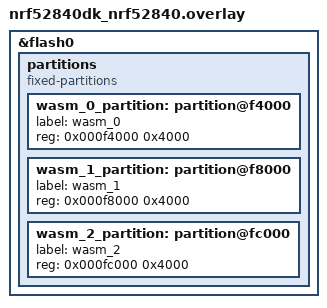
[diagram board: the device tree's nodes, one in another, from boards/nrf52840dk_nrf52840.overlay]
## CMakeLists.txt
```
cmake_minimum_required(VERSION 3.14)

find_package(Zephyr REQUIRED HINTS $ENV{ZEPHYR_BASE})
project(wamr_ota)

enable_language(ASM)

set(WAMR_BUILD_PLATFORM "zephyr")

if(NOT DEFINED WAMR_BUILD_TARGET)
  set(WAMR_BUILD_TARGET "THUMBV7")
endif()

set(WAMR_BUILD_INTERP 1)
set(WAMR_BUILD_FAST_INTERP 1)
set(WAMR_BUILD_AOT 0)
set(WAMR_BUILD_JIT 0)
set(WAMR_BUILD_LIBC_BUILTIN 1)
set(WAMR_BUILD_LIBC_WASI 0)
set(WAMR_BUILD_MINI_LOADER 0)
set(WAMR_BUILD_MULTI_MODULE 0)
set(WAMR_BUILD_REF_TYPES 0)
set(WAMR_BUILD_SIMD 0)

set(WAMR_BUILD_GLOBAL_HEAP_POOL 1)

if(BOARD STREQUAL "nucleo_l476rg")
  set(WAMR_BUILD_GLOBAL_HEAP_SIZE 73728)
  set(WASM_OTA_BUF_SIZE 2048)
  set(WASM_STACK_SIZE 2048)
  set(WASM_HEAP_SIZE 2048)
else()
  set(WAMR_BUILD_GLOBAL_HEAP_SIZE 225280)
  set(WASM_OTA_BUF_SIZE 8192)
  set(WASM_STACK_SIZE 2048)
  set(WASM_HEAP_SIZE 0)
endif()

if(EXISTS ${CMAKE_CURRENT_SOURCE_DIR}/../wasm-micro-runtime)
  set(WAMR_ROOT_DIR ${CMAKE_CURRENT_SOURCE_DIR}/../wasm-micro-runtime)
else()
  set(WAMR_ROOT_DIR ${CMAKE_CURRENT_SOURCE_DIR}/../modules/wasm-micro-runtime)
endif()

include(${WAMR_ROOT_DIR}/build-scripts/runtime_lib.cmake)

target_sources(app PRIVATE
    ${WAMR_RUNTIME_LIB_SOURCE}
    src/main.c
    src/supervisor.c
    src/wasm_runner.c
    src/uart_loader.c
    src/wasm_flash.c
    src/native_api.c
)

target_compile_definitions(app PRIVATE
    WASM_OTA_BUF_SIZE=${WASM_OTA_BUF_SIZE}
    WASM_STACK_SIZE=${WASM_STACK_SIZE}
    WASM_HEAP_SIZE=${WASM_HEAP_SIZE}
)
target_compile_options(app PRIVATE -Wno-type-limits)
```

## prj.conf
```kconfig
CONFIG_STACK_SENTINEL=y
CONFIG_PRINTK=y
CONFIG_LOG=y
CONFIG_LOG_BUFFER_SIZE=4096

# Keep stacks small to leave RAM for WAMR heap
CONFIG_MAIN_STACK_SIZE=2048

# UART for OTA wasm upload (shared with console)
CONFIG_SERIAL=y
CONFIG_UART_INTERRUPT_DRIVEN=y
CONFIG_RING_BUFFER=y

# CRC-32 for upload validation
CONFIG_CRC=y
```

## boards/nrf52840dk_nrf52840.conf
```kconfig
CONFIG_ARM_MPU=y
CONFIG_GPIO=y
CONFIG_LOG_BUFFER_SIZE=4096

# Flash persistence for OTA wasm
CONFIG_FLASH=y
CONFIG_FLASH_MAP=y
```

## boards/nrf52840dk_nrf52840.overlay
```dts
&flash0 {
	partitions {
		compatible = "fixed-partitions";
		#address-cells = <1>;
		#size-cells = <1>;

		wasm_0_partition: partition@f4000 {
			label = "wasm_0";
			reg = <0x000f4000 0x4000>;
		};

		wasm_1_partition: partition@f8000 {
			label = "wasm_1";
			reg = <0x000f8000 0x4000>;
		};

		wasm_2_partition: partition@fc000 {
			label = "wasm_2";
			reg = <0x000fc000 0x4000>;
		};
	};
};
```

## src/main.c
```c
#include <stdlib.h>
#include <string.h>
#include <zephyr/kernel.h>
#include "wasm_export.h"
#include "supervisor.h"
#include "native_api.h"

static char global_heap_buf[WASM_GLOBAL_HEAP_SIZE];

int main(void)
{
    printk("--- WAMR Multi-Module Runtime ---\n");

    if (native_api_init() != 0) {
        printk("GPIO init failed\n");
        return 1;
    }

    RuntimeInitArgs init_args;
    memset(&init_args, 0, sizeof(init_args));
    init_args.mem_alloc_type = Alloc_With_Pool;
    init_args.mem_alloc_option.pool.heap_buf = global_heap_buf;
    init_args.mem_alloc_option.pool.heap_size = sizeof(global_heap_buf);

    if (!wasm_runtime_full_init(&init_args)) {
        printk("WAMR init failed\n");
        return 1;
    }

    native_api_register();

    supervisor_start();
    return 0;
}
```

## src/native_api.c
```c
#include <zephyr/kernel.h>
#include <zephyr/drivers/gpio.h>
#include "wasm_export.h"
#include "native_api.h"

#define NUM_BUTTONS 4
#define NUM_LEDS    4
#define NUM_DATA    16

static const struct gpio_dt_spec buttons[NUM_BUTTONS] = {
    GPIO_DT_SPEC_GET(DT_ALIAS(sw0), gpios),
    GPIO_DT_SPEC_GET(DT_ALIAS(sw1), gpios),
    GPIO_DT_SPEC_GET(DT_ALIAS(sw2), gpios),
    GPIO_DT_SPEC_GET(DT_ALIAS(sw3), gpios),
};

static const struct gpio_dt_spec leds[NUM_LEDS] = {
    GPIO_DT_SPEC_GET(DT_ALIAS(led0), gpios),
    GPIO_DT_SPEC_GET(DT_ALIAS(led1), gpios),
    GPIO_DT_SPEC_GET(DT_ALIAS(led2), gpios),
    GPIO_DT_SPEC_GET(DT_ALIAS(led3), gpios),
};

static int32_t shared_data[NUM_DATA];

static int32_t
native_read_button(wasm_exec_env_t exec_env, int32_t n)
{
    (void)exec_env;
    if (n < 0 || n >= NUM_BUTTONS)
        return -1;
    return gpio_pin_get_dt(&buttons[n]);
}

static void
native_set_led(wasm_exec_env_t exec_env, int32_t n, int32_t on)
{
    (void)exec_env;
    if (n >= 0 && n < NUM_LEDS)
        gpio_pin_set_dt(&leds[n], on ? 1 : 0);
}

static void
native_set_data(wasm_exec_env_t exec_env, int32_t key, int32_t value)
{
    (void)exec_env;
    if (key >= 0 && key < NUM_DATA)
        shared_data[key] = value;
}

static int32_t
native_get_data(wasm_exec_env_t exec_env, int32_t key)
{
    (void)exec_env;
    if (key < 0 || key >= NUM_DATA)
        return 0;
    return shared_data[key];
}

static NativeSymbol native_symbols[] = {
    { "read_button", native_read_button, "(i)i", NULL },
    { "set_led",     native_set_led,     "(ii)", NULL },
    { "set_data",    native_set_data,    "(ii)", NULL },
    { "get_data",    native_get_data,    "(i)i", NULL },
};

int
native_api_init(void)
{
    for (int i = 0; i < NUM_BUTTONS; i++) {
        if (!gpio_is_ready_dt(&buttons[i])) {
            printk("[native] button %d not ready\n", i);
            return -1;
        }
        gpio_pin_configure_dt(&buttons[i], GPIO_INPUT);
    }

    for (int i = 0; i < NUM_LEDS; i++) {
        if (!gpio_is_ready_dt(&leds[i])) {
            printk("[native] LED %d not ready\n", i);
            return -1;
        }
        gpio_pin_configure_dt(&leds[i], GPIO_OUTPUT_INACTIVE);
    }

    memset(shared_data, 0, sizeof(shared_data));
    printk("[native] GPIO ready: %d buttons, %d LEDs\n", NUM_BUTTONS, NUM_LEDS);
    return 0;
}

void
native_api_register(void)
{
    wasm_runtime_register_natives("env", native_symbols,
                                 sizeof(native_symbols) / sizeof(NativeSymbol));
}
```

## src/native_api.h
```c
#ifndef NATIVE_API_H
#define NATIVE_API_H

int native_api_init(void);

void native_api_register(void);

#endif
```

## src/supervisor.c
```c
#include <zephyr/kernel.h>
#include "supervisor.h"
#include "wasm_runner.h"
#include "wasm_flash.h"
#include "uart_loader.h"

#define SUPERVISOR_STACK_SIZE 2048
#define WASM_BUF_SIZE 8192

static uint8_t wasm_buf[WASM_BUF_SIZE];

static K_THREAD_STACK_DEFINE(supervisor_stack, SUPERVISOR_STACK_SIZE);
static struct k_thread supervisor_thread;

/* Embedded defaults for first boot (generated by build.sh) */
#include "wasm_sensor.h"
#include "wasm_actuator.h"
#include "wasm_alert.h"

static const char *slot_names[] = { "sensor", "actuator", "alert" };

struct embedded_default {
    unsigned char *data;
    unsigned int *len;
};

static struct embedded_default defaults[WASM_NUM_SLOTS];

static bool
load_slot(int slot)
{
    uint32_t size = wasm_flash_read(slot, wasm_buf, sizeof(wasm_buf));
    if (size == 0)
        return false;
    return wasm_runner_load(slot, slot_names[slot], wasm_buf, size);
}

static void
supervisor_entry(void *p1, void *p2, void *p3)
{
    (void)p1; (void)p2; (void)p3;

    defaults[0] = (struct embedded_default){ wasm_sensor, &wasm_sensor_len };
    defaults[1] = (struct embedded_default){ wasm_actuator, &wasm_actuator_len };
    defaults[2] = (struct embedded_default){ wasm_alert, &wasm_alert_len };

    wasm_runner_init();

    if (wasm_flash_init() != 0) {
        printk("[supervisor] flash init failed\n");
        return;
    }

    if (uart_loader_init() != 0) {
        printk("[supervisor] UART init failed\n");
        return;
    }

    /* Load all modules from flash (write defaults on first boot) */
    for (int i = 0; i < WASM_NUM_SLOTS; i++) {
        if (!wasm_flash_valid(i)) {
            printk("[supervisor] writing default %s to slot %d\n",
                   slot_names[i], i);
            wasm_flash_write(i, defaults[i].data, *defaults[i].len);
        }
        if (!load_slot(i)) {
            printk("[supervisor] slot %d (%s) failed to load!\n",
                   i, slot_names[i]);
        }
    }

    printk("[supervisor] all modules loaded, running...\n");

    while (1) {
        /* Run all loaded modules (no load/unload per cycle) */
        wasm_runner_run_all();

        /* Check for OTA upload */
        uint32_t wasm_size = 0;
        int target_slot = -1;
        int result = uart_loader_poll(wasm_buf, sizeof(wasm_buf),
                                      &wasm_size, &target_slot, 50);

        switch (result) {
        case LOADER_COMPLETE:
            if (target_slot < 0 || target_slot >= WASM_NUM_SLOTS) {
                uart_loader_respond("ERR:SLOT\n");
                break;
            }

            printk("[supervisor] OTA slot %d (%s): %u bytes\n",
                   target_slot, slot_names[target_slot], wasm_size);

            if (wasm_flash_write(target_slot, wasm_buf, wasm_size) != 0) {
                uart_loader_respond("ERR:FLASH\n");
                break;
            }

            /* Unload old, reload from flash */
            wasm_runner_unload(target_slot);
            if (load_slot(target_slot)) {
                uart_loader_respond("OK\n");
                printk("[supervisor] %s updated\n", slot_names[target_slot]);
            } else {
                uart_loader_respond("ERR:LOAD\n");
                printk("[supervisor] reload failed, restoring default\n");
                wasm_flash_write(target_slot, defaults[target_slot].data,
                                 *defaults[target_slot].len);
                load_slot(target_slot);
            }
            break;

        case LOADER_ERR_CRC:
            uart_loader_respond("ERR:CRC\n");
            break;

        case LOADER_ERR_SIZE:
            uart_loader_respond("ERR:SIZE\n");
            break;

        case LOADER_STATUS:
            uart_loader_respond("RUNNING\n");
            break;

        default:
            break;
        }

        k_sleep(K_MSEC(50));
    }
}

void
supervisor_start(void)
{
    k_thread_create(&supervisor_thread, supervisor_stack,
                    SUPERVISOR_STACK_SIZE, supervisor_entry,
                    NULL, NULL, NULL, 3, 0, K_NO_WAIT);
    k_thread_name_set(&supervisor_thread, "supervisor");
}
```

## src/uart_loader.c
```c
#include <string.h>
#include <zephyr/kernel.h>
#include <zephyr/device.h>
#include <zephyr/drivers/uart.h>
#include <zephyr/sys/ring_buffer.h>
#include <zephyr/sys/crc.h>
#include "uart_loader.h"

#define UART_RING_BUF_SIZE 1024

static const uint8_t MAGIC[4] = { 'W', 'A', 'S', 'M' };

typedef enum {
    RX_IDLE,
    RX_HEADER,
    RX_PAYLOAD,
    RX_CRC,
} rx_state_t;

static const struct device *uart_dev;
static uint8_t ring_buf_data[UART_RING_BUF_SIZE];
static struct ring_buf rx_ring;

static rx_state_t rx_state;
static uint8_t magic_window[4];
static uint8_t header_buf[7];
static uint32_t header_pos;
static uint32_t payload_pos;
static uint32_t expected_size;
static uint8_t expected_cmd;
static uint8_t expected_slot;
static uint8_t crc_buf[4];
static uint32_t crc_pos;

static int *slot_out_ptr;

static void
uart_isr_callback(const struct device *dev, void *user_data)
{
    (void)user_data;

    while (uart_irq_update(dev) && uart_irq_is_pending(dev)) {
        if (uart_irq_rx_ready(dev)) {
            uint8_t buf[64];
            int len = uart_fifo_read(dev, buf, sizeof(buf));
            if (len > 0)
                ring_buf_put(&rx_ring, buf, len);
        }
    }
}

int
uart_loader_init(void)
{
    uart_dev = DEVICE_DT_GET(DT_CHOSEN(zephyr_console));
    if (!device_is_ready(uart_dev)) {
        printk("[loader] UART device not ready\n");
        return -1;
    }

    ring_buf_init(&rx_ring, sizeof(ring_buf_data), ring_buf_data);

    uart_irq_callback_set(uart_dev, uart_isr_callback);
    uart_irq_rx_enable(uart_dev);

    rx_state = RX_IDLE;
    memset(magic_window, 0, sizeof(magic_window));

    printk("[loader] UART RX ready\n");
    return 0;
}

void
uart_loader_respond(const char *msg)
{
    while (*msg) {
        uart_poll_out(uart_dev, *msg++);
    }
}

static int
process_byte(uint8_t b, uint8_t *buf, uint32_t buf_size, uint32_t *out_size)
{
    switch (rx_state) {
    case RX_IDLE:
        memmove(magic_window, magic_window + 1, 3);
        magic_window[3] = b;
        if (memcmp(magic_window, MAGIC, 4) == 0) {
            rx_state = RX_HEADER;
            header_pos = 0;
            memset(magic_window, 0, sizeof(magic_window));
        }
        break;

    case RX_HEADER:
        header_buf[header_pos++] = b;
        /* Header: CMD(1) + SLOT(1) + SIZE(4) + '\n'(1) = 7 bytes */
        if (header_pos == 7) {
            expected_cmd = header_buf[0];
            expected_slot = header_buf[1];
            expected_size = header_buf[2]
                          | (header_buf[3] << 8)
                          | (header_buf[4] << 16)
                          | (header_buf[5] << 24);

            if (slot_out_ptr)
                *slot_out_ptr = expected_slot;

            if (expected_cmd == CMD_STATUS) {
                rx_state = RX_IDLE;
                *out_size = 0;
                return LOADER_STATUS;
            }

            if (expected_size == 0 || expected_size > buf_size) {
                printk("[loader] size %u exceeds buffer %u\n",
                       expected_size, buf_size);
                rx_state = RX_IDLE;
                return LOADER_ERR_SIZE;
            }

            payload_pos = 0;
            rx_state = RX_PAYLOAD;
        }
        break;

    case RX_PAYLOAD:
        buf[payload_pos++] = b;
        if (payload_pos == expected_size) {
            crc_pos = 0;
            rx_state = RX_CRC;
        }
        break;

    case RX_CRC:
        crc_buf[crc_pos++] = b;
        if (crc_pos == 4) {
            uint32_t received_crc = crc_buf[0]
                                  | (crc_buf[1] << 8)
                                  | (crc_buf[2] << 16)
                                  | (crc_buf[3] << 24);
            uint32_t computed_crc = crc32_ieee(buf, expected_size);

            rx_state = RX_IDLE;

            if (received_crc != computed_crc) {
                printk("[loader] CRC mismatch: got 0x%08x, expected 0x%08x\n",
                       received_crc, computed_crc);
                return LOADER_ERR_CRC;
            }

            *out_size = expected_size;
            return LOADER_COMPLETE;
        }
        break;
    }

    return (rx_state == RX_IDLE) ? LOADER_IDLE : LOADER_RECEIVING;
}

int
uart_loader_poll(uint8_t *buf, uint32_t buf_size,
                 uint32_t *out_size, int *out_slot,
                 int32_t timeout_ms)
{
    int64_t deadline = k_uptime_get() + timeout_ms;
    int result = LOADER_IDLE;

    slot_out_ptr = out_slot;

    while (k_uptime_get() < deadline) {
        uint8_t b;
        if (ring_buf_get(&rx_ring, &b, 1) == 1) {
            result = process_byte(b, buf, buf_size, out_size);
            if (result != LOADER_IDLE && result != LOADER_RECEIVING)
                return result;
        } else {
            k_sleep(K_MSEC(1));
        }
    }

    return result;
}
```

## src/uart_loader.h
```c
#ifndef UART_LOADER_H
#define UART_LOADER_H

#include <stdint.h>

#define LOADER_IDLE       0
#define LOADER_RECEIVING  1
#define LOADER_COMPLETE   2
#define LOADER_STATUS     3
#define LOADER_ERR_CRC   -1
#define LOADER_ERR_SIZE  -2

#define CMD_UPLOAD  0x01
#define CMD_STATUS  0x02

int uart_loader_init(void);

int uart_loader_poll(uint8_t *buf, uint32_t buf_size,
                     uint32_t *out_size, int *out_slot,
                     int32_t timeout_ms);

void uart_loader_respond(const char *msg);

#endif
```

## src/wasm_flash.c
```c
#include <string.h>
#include <zephyr/kernel.h>
#include <zephyr/storage/flash_map.h>
#include <zephyr/sys/crc.h>
#include "wasm_flash.h"

#define WASM_SLOT_MAGIC  0x4D534157
#define HEADER_SIZE      32
#define DATA_OFFSET      HEADER_SIZE
#define ALIGN4(x)        (((x) + 3) & ~3)

struct wasm_slot_header {
    uint32_t magic;
    uint32_t size;
    uint32_t crc32;
    uint32_t version;
    uint8_t  reserved[16];
};

static const struct flash_area *slot_fa[WASM_NUM_SLOTS];
static bool initialized;

static const int slot_partition_ids[WASM_NUM_SLOTS] = {
    FIXED_PARTITION_ID(wasm_0_partition),
    FIXED_PARTITION_ID(wasm_1_partition),
    FIXED_PARTITION_ID(wasm_2_partition),
};

int
wasm_flash_init(void)
{
    for (int i = 0; i < WASM_NUM_SLOTS; i++) {
        int rc = flash_area_open(slot_partition_ids[i], &slot_fa[i]);
        if (rc) {
            printk("[flash] failed to open slot %d: %d\n", i, rc);
            return rc;
        }
    }

    printk("[flash] %d slots ready (%u bytes each)\n",
           WASM_NUM_SLOTS, (unsigned)slot_fa[0]->fa_size);

    initialized = true;
    return 0;
}

static bool
read_header(int slot, struct wasm_slot_header *hdr)
{
    if (!initialized || slot < 0 || slot >= WASM_NUM_SLOTS)
        return false;
    return flash_area_read(slot_fa[slot], 0, hdr, sizeof(*hdr)) == 0;
}

bool
wasm_flash_valid(int slot)
{
    struct wasm_slot_header hdr;

    if (!read_header(slot, &hdr))
        return false;

    if (hdr.magic != WASM_SLOT_MAGIC)
        return false;

    if (hdr.size == 0 || hdr.size > slot_fa[slot]->fa_size - DATA_OFFSET)
        return false;

    uint8_t buf[256];
    uint32_t crc = 0;
    uint32_t remaining = hdr.size;
    uint32_t offset = DATA_OFFSET;

    while (remaining > 0) {
        uint32_t chunk = remaining < sizeof(buf) ? remaining : sizeof(buf);
        if (flash_area_read(slot_fa[slot], offset, buf, chunk) != 0)
            return false;
        crc = crc32_ieee_update(crc, buf, chunk);
        offset += chunk;
        remaining -= chunk;
    }

    return crc == hdr.crc32;
}

uint32_t
wasm_flash_version(int slot)
{
    struct wasm_slot_header hdr;
    if (!read_header(slot, &hdr) || hdr.magic != WASM_SLOT_MAGIC)
        return 0;
    return hdr.version;
}

uint32_t
wasm_flash_read(int slot, uint8_t *buf, uint32_t buf_size)
{
    struct wasm_slot_header hdr;
    if (!read_header(slot, &hdr))
        return 0;
    if (hdr.magic != WASM_SLOT_MAGIC || hdr.size == 0)
        return 0;
    if (hdr.size > buf_size)
        return 0;
    if (flash_area_read(slot_fa[slot], DATA_OFFSET, buf, hdr.size) != 0)
        return 0;

    uint32_t crc = crc32_ieee(buf, hdr.size);
    if (crc != hdr.crc32) {
        printk("[flash] slot %d CRC mismatch\n", slot);
        return 0;
    }

    return hdr.size;
}

int
wasm_flash_write(int slot, const uint8_t *data, uint32_t size)
{
    if (!initialized || slot < 0 || slot >= WASM_NUM_SLOTS)
        return -1;

    if (size + DATA_OFFSET > slot_fa[slot]->fa_size)
        return -1;

    struct wasm_slot_header hdr;
    memset(&hdr, 0, sizeof(hdr));
    hdr.magic = WASM_SLOT_MAGIC;
    hdr.size = size;
    hdr.crc32 = crc32_ieee(data, size);
    hdr.version = wasm_flash_version(slot) + 1;

    int rc = flash_area_erase(slot_fa[slot], 0, slot_fa[slot]->fa_size);
    if (rc) return rc;

    rc = flash_area_write(slot_fa[slot], 0, &hdr, sizeof(hdr));
    if (rc) return rc;

    uint32_t write_size = ALIGN4(size);
    if (write_size == size) {
        rc = flash_area_write(slot_fa[slot], DATA_OFFSET, data, size);
    } else {
        rc = flash_area_write(slot_fa[slot], DATA_OFFSET, data, size & ~3);
        if (rc == 0) {
            uint8_t pad[4] = {0xFF, 0xFF, 0xFF, 0xFF};
            memcpy(pad, data + (size & ~3), size & 3);
            rc = flash_area_write(slot_fa[slot], DATA_OFFSET + (size & ~3), pad, 4);
        }
    }
    if (rc) return rc;

    printk("[flash] wrote slot %d: %u bytes, v%u\n", slot, size, hdr.version);
    return 0;
}
```

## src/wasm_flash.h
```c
#ifndef WASM_FLASH_H
#define WASM_FLASH_H

#include <stdint.h>
#include <stdbool.h>

#define WASM_NUM_SLOTS  3
#define WASM_SLOT_SENSOR   0
#define WASM_SLOT_ACTUATOR 1
#define WASM_SLOT_ALERT    2

int wasm_flash_init(void);

bool wasm_flash_valid(int slot);

uint32_t wasm_flash_version(int slot);

uint32_t wasm_flash_read(int slot, uint8_t *buf, uint32_t buf_size);

int wasm_flash_write(int slot, const uint8_t *data, uint32_t size);

#endif
```

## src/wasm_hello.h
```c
unsigned char wasm_hello[] = {
  0x00, 0x61, 0x73, 0x6d, 0x01, 0x00, 0x00, 0x00, 0x01, 0x0b, 0x02, 0x60,
  0x02, 0x7f, 0x7f, 0x01, 0x7f, 0x60, 0x00, 0x01, 0x7f, 0x02, 0x0e, 0x01,
  0x03, 0x65, 0x6e, 0x76, 0x06, 0x70, 0x72, 0x69, 0x6e, 0x74, 0x66, 0x00,
  0x00, 0x03, 0x03, 0x02, 0x01, 0x00, 0x04, 0x05, 0x01, 0x70, 0x01, 0x01,
  0x01, 0x05, 0x03, 0x01, 0x00, 0x01, 0x06, 0x07, 0x01, 0x7f, 0x01, 0x41,
  0x80, 0x20, 0x0b, 0x07, 0x11, 0x02, 0x06, 0x6d, 0x65, 0x6d, 0x6f, 0x72,
  0x79, 0x02, 0x00, 0x04, 0x6d, 0x61, 0x69, 0x6e, 0x00, 0x02, 0x0a, 0x1e,
  0x02, 0x13, 0x00, 0x41, 0x80, 0xa0, 0x80, 0x80, 0x00, 0x41, 0x00, 0x10,
  0x80, 0x80, 0x80, 0x80, 0x00, 0x1a, 0x41, 0x00, 0x0b, 0x08, 0x00, 0x10,
  0x81, 0x80, 0x80, 0x80, 0x00, 0x0b, 0x0b, 0x26, 0x01, 0x00, 0x41, 0x80,
  0x20, 0x0b, 0x1f, 0x48, 0x65, 0x6c, 0x6c, 0x6f, 0x20, 0x57, 0x6f, 0x72,
  0x6c, 0x64, 0x20, 0x66, 0x72, 0x6f, 0x6d, 0x20, 0x57, 0x65, 0x62, 0x41,
  0x73, 0x73, 0x65, 0x6d, 0x62, 0x6c, 0x79, 0x21, 0x0a, 0x00, 0x00, 0x5a,
  0x04, 0x6e, 0x61, 0x6d, 0x65, 0x00, 0x11, 0x10, 0x68, 0x65, 0x6c, 0x6c,
  0x6f, 0x5f, 0x73, 0x6d, 0x61, 0x6c, 0x6c, 0x2e, 0x77, 0x61, 0x73, 0x6d,
  0x01, 0x20, 0x03, 0x00, 0x06, 0x70, 0x72, 0x69, 0x6e, 0x74, 0x66, 0x01,
  0x0f, 0x5f, 0x5f, 0x6f, 0x72, 0x69, 0x67, 0x69, 0x6e, 0x61, 0x6c, 0x5f,
  0x6d, 0x61, 0x69, 0x6e, 0x02, 0x04, 0x6d, 0x61, 0x69, 0x6e, 0x07, 0x12,
  0x01, 0x00, 0x0f, 0x5f, 0x5f, 0x73, 0x74, 0x61, 0x63, 0x6b, 0x5f, 0x70,
  0x6f, 0x69, 0x6e, 0x74, 0x65, 0x72, 0x09, 0x0a, 0x01, 0x00, 0x07, 0x2e,
  0x72, 0x6f, 0x64, 0x61, 0x74, 0x61, 0x00, 0x7f, 0x09, 0x70, 0x72, 0x6f,
  0x64, 0x75, 0x63, 0x65, 0x72, 0x73, 0x01, 0x0c, 0x70, 0x72, 0x6f, 0x63,
  0x65, 0x73, 0x73, 0x65, 0x64, 0x2d, 0x62, 0x79, 0x01, 0x05, 0x63, 0x6c,
  0x61, 0x6e, 0x67, 0x5f, 0x32, 0x32, 0x2e, 0x31, 0x2e, 0x30, 0x2d, 0x77,
  0x61, 0x73, 0x69, 0x2d, 0x73, 0x64, 0x6b, 0x20, 0x28, 0x68, 0x74, 0x74,
  0x70, 0x73, 0x3a, 0x2f, 0x2f, 0x67, 0x69, 0x74, 0x68, 0x75, 0x62, 0x2e,
  0x63, 0x6f, 0x6d, 0x2f, 0x6c, 0x6c, 0x76, 0x6d, 0x2f, 0x6c, 0x6c, 0x76,
  0x6d, 0x2d, 0x70, 0x72, 0x6f, 0x6a, 0x65, 0x63, 0x74, 0x20, 0x34, 0x34,
  0x33, 0x34, 0x64, 0x61, 0x62, 0x62, 0x36, 0x39, 0x39, 0x31, 0x36, 0x38,
  0x35, 0x36, 0x62, 0x38, 0x32, 0x34, 0x66, 0x36, 0x38, 0x61, 0x36, 0x34,
  0x62, 0x30, 0x32, 0x39, 0x63, 0x36, 0x37, 0x31, 0x37, 0x35, 0x65, 0x35,
  0x33, 0x32, 0x29, 0x00, 0x94, 0x01, 0x0f, 0x74, 0x61, 0x72, 0x67, 0x65,
  0x74, 0x5f, 0x66, 0x65, 0x61, 0x74, 0x75, 0x72, 0x65, 0x73, 0x08, 0x2b,
  0x0b, 0x62, 0x75, 0x6c, 0x6b, 0x2d, 0x6d, 0x65, 0x6d, 0x6f, 0x72, 0x79,
  0x2b, 0x0f, 0x62, 0x75, 0x6c, 0x6b, 0x2d, 0x6d, 0x65, 0x6d, 0x6f, 0x72,
  0x79, 0x2d, 0x6f, 0x70, 0x74, 0x2b, 0x16, 0x63, 0x61, 0x6c, 0x6c, 0x2d,
  0x69, 0x6e, 0x64, 0x69, 0x72, 0x65, 0x63, 0x74, 0x2d, 0x6f, 0x76, 0x65,
  0x72, 0x6c, 0x6f, 0x6e, 0x67, 0x2b, 0x0a, 0x6d, 0x75, 0x6c, 0x74, 0x69,
  0x76, 0x61, 0x6c, 0x75, 0x65, 0x2b, 0x0f, 0x6d, 0x75, 0x74, 0x61, 0x62,
  0x6c, 0x65, 0x2d, 0x67, 0x6c, 0x6f, 0x62, 0x61, 0x6c, 0x73, 0x2b, 0x13,
  0x6e, 0x6f, 0x6e, 0x74, 0x72, 0x61, 0x70, 0x70, 0x69, 0x6e, 0x67, 0x2d,
  0x66, 0x70, 0x74, 0x6f, 0x69, 0x6e, 0x74, 0x2b, 0x0f, 0x72, 0x65, 0x66,
  0x65, 0x72, 0x65, 0x6e, 0x63, 0x65, 0x2d, 0x74, 0x79, 0x70, 0x65, 0x73,
  0x2b, 0x08, 0x73, 0x69, 0x67, 0x6e, 0x2d, 0x65, 0x78, 0x74
};
unsigned int wasm_hello_len = 526;
```

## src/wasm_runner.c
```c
#include <stdlib.h>
#include <string.h>
#include <zephyr/kernel.h>
#include "wasm_export.h"
#include "wasm_runner.h"

#define WASM_STACK_SIZE 2048
#define WASM_HEAP_SIZE  1024

bool
wasm_application_execute_main(wasm_module_inst_t module_inst, int32_t argc,
                              char *argv[]);

static const char *slot_names[MAX_MODULES] = { "sensor", "actuator", "alert" };

static struct {
    wasm_module_t module;
    wasm_module_inst_t inst;
} modules[MAX_MODULES];

void
wasm_runner_init(void)
{
    memset(modules, 0, sizeof(modules));
}

bool
wasm_runner_load(int slot, const char *name, uint8_t *buf, uint32_t size)
{
    if (slot < 0 || slot >= MAX_MODULES)
        return false;

    wasm_runner_unload(slot);

    char error_buf[64];
    LoadArgs load_args = { 0 };
    load_args.wasm_binary_freeable = true;

    modules[slot].module = wasm_runtime_load_ex(
        buf, size, &load_args, error_buf, sizeof(error_buf));
    if (!modules[slot].module) {
        printk("[runner] load %s failed: %s\n", name, error_buf);
        return false;
    }

    modules[slot].inst = wasm_runtime_instantiate(
        modules[slot].module, WASM_STACK_SIZE, WASM_HEAP_SIZE,
        error_buf, sizeof(error_buf));
    if (!modules[slot].inst) {
        printk("[runner] instantiate %s failed: %s\n", name, error_buf);
        wasm_runtime_unload(modules[slot].module);
        modules[slot].module = NULL;
        return false;
    }

    printk("[runner] %s loaded and ready\n", name);
    return true;
}

void
wasm_runner_unload(int slot)
{
    if (slot < 0 || slot >= MAX_MODULES)
        return;
    if (modules[slot].inst) {
        wasm_runtime_deinstantiate(modules[slot].inst);
        modules[slot].inst = NULL;
    }
    if (modules[slot].module) {
        wasm_runtime_unload(modules[slot].module);
        modules[slot].module = NULL;
    }
}

bool
wasm_runner_run(int slot)
{
    if (slot < 0 || slot >= MAX_MODULES || !modules[slot].inst)
        return false;

    wasm_application_execute_main(modules[slot].inst, 0, NULL);

    const char *exc = wasm_runtime_get_exception(modules[slot].inst);
    if (exc) {
        printk("[runner] %s exception: %s\n", slot_names[slot], exc);
        wasm_runtime_clear_exception(modules[slot].inst);
        return false;
    }
    return true;
}

void
wasm_runner_run_all(void)
{
    for (int i = 0; i < MAX_MODULES; i++) {
        if (modules[i].inst)
            wasm_runner_run(i);
    }
}

bool
wasm_runner_loaded(int slot)
{
    if (slot < 0 || slot >= MAX_MODULES)
        return false;
    return modules[slot].inst != NULL;
}
```

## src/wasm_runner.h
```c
#ifndef WASM_RUNNER_H
#define WASM_RUNNER_H

#include <stdint.h>
#include <stdbool.h>

#define MAX_MODULES 3

void wasm_runner_init(void);

bool wasm_runner_load(int slot, const char *name, uint8_t *buf, uint32_t size);

void wasm_runner_unload(int slot);

bool wasm_runner_run(int slot);

void wasm_runner_run_all(void);

bool wasm_runner_loaded(int slot);

#endif
```
